# DSS_PRM register map
Vendor: Texas Instruments
Peripheral module from a debugger description file (folder omap5430_ES2_PUBLIC).
Registers are 32-bit, access not given, reset 0x30000 unless marked. A register's access mark holds for its fields unless they carry their own. Offsets are as the file gives them; lines under a group give offsets from that group; [hi:lo] are bit positions; {n}, {i} and the like mark numbered series; 'fields as' and 'values as' point back to an identical list; <NAME> marks a mode.

## DSS_PRM
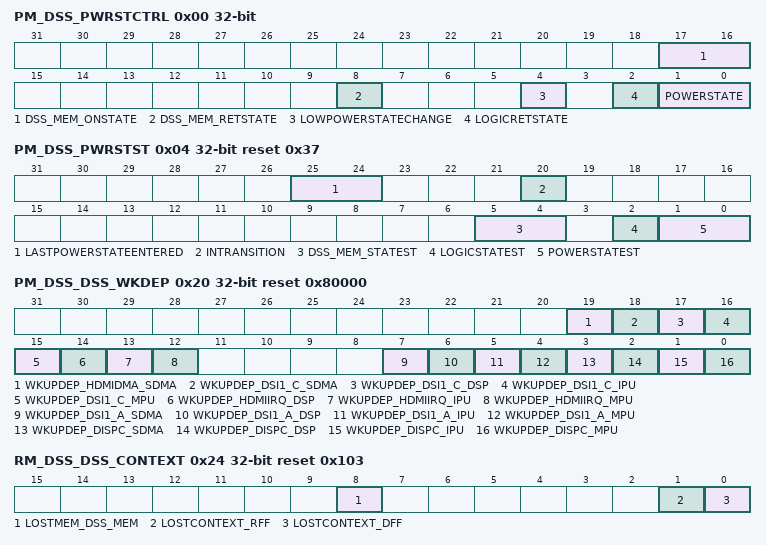
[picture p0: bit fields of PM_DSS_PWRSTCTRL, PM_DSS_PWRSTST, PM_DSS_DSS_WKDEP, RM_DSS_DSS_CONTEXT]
0x00 PM_DSS_PWRSTCTRL — This register controls the DSS power state to reach upon a domain sleep transition
  [17:16] DSS_MEM_ONSTATE ro — DSS_MEM state when domain is ON.
    3=Mem_on (Memory bank is on when the domain is ON.)
  [8] DSS_MEM_RETSTATE ro — DSS_MEM state when domain is RETENTION.
    0=mem_off (Memory bank is off when the domain is in the RETENTION state.)
  [4] LOWPOWERSTATECHANGE — Power state change request when domain has already performed a sleep transition. Allows going into deeper low power state without waking up the power domain. (access RW WSpecial)
    0=DIS (Do not request a low power state change.); 1=EN (Request a low power state change. This bit is automatically cleared when the power state is effectively changed or when power state is ON.)
  [2] LOGICRETSTATE ro — Logic state when power domain is RETENTION
    0=logic_off (Whole logic is off when the domain is in RETENTION state.)
  [1:0] POWERSTATE rw — Power state control
    0=OFF (Reserved); 1=RET (RETENTION state); 2=INACT (INACTIVE state); 3=ON (ON State)
0x04 PM_DSS_PWRSTST reset 0x37 — This register provides a status on the current DSS power domain state. [warm reset insensitive]
  [25:24] LASTPOWERSTATEENTERED — Last low power state entered. Set to 0x3 upon write of the same only. This register is intended for debug purpose only. Read 0x0: Reserved Read 0x1: Power domain was previously in RETENTION Read 0x2: Power domain was previously ON-INACTIVE Read 0x3: Power domain was previously ON-ACTIVE (access RW W1toSet)
  [20] INTRANSITION ro — Domain transition status
    0=No (No on-going transition on power domain); 1=Ongoing (Power domain transition is in progress.)
  [5:4] DSS_MEM_STATEST ro — DSS_MEM state status
    0=Mem_off (Reserved); 3=Mem_on (Memory is ON)
  [2] LOGICSTATEST ro — Logic state status
    0=OFF (Logic in domain is OFF); 1=ON (Logic in domain is ON)
  [1:0] POWERSTATEST ro — Current power state status
    0=OFF (Reserved); 1=RET (Power domain is in RETENTION); 2=INACTIVE (Power domain is ON-INACTIVE); 3=ON (Power domain is ON-ACTIVE)
0x20 PM_DSS_DSS_WKDEP access per field reset 0x80000 — This register controls wakeup dependency based on DSS service requests.
  [19] WKUPDEP_HDMIDMA_SDMA rw — Wakeup dependency from HDMI module (SWakeup_HDMI_dma signal) towards DMA_SYSTEM + L3_MAIN2 domains
    0=Disabled (Dependency is disabled); 1=Enabled (Dependency is enabled)
  [18] WKUPDEP_DSI1_C_SDMA rw — Wakeup dependency from DSI1_C module (SWakeup_DSI1_C signal) towards DMA_SYSTEM + L3_MAIN2 domains 0x0: Dependency is disabled 0x1: Dependency is enabled
  [17] WKUPDEP_DSI1_C_DSP rw — Wakeup dependency from DSI1_C module (SWakeup_DSI1_C signal) towards DSP + L3_MAIN1 + L3_MAIN2 domains 0x0: Dependency is disabled 0x1: Dependency is enabled
  [16] WKUPDEP_DSI1_C_IPU rw — Wakeup dependency from DSI1_C module (SWakeup_DSI1_C signal) towards IPU + L3_MAIN2 domains 0x0: Dependency is disabled 0x1: Dependency is enabled
  [15] WKUPDEP_DSI1_C_MPU rw — Wakeup dependency from DSI1_C module (SWakeup_DSI1_C signal) towards MPU + L3_MAIN1 + L3_MAIN2 domains 0x0: Dependency is disabled 0x1: Dependency is enabled
  [14] WKUPDEP_HDMIIRQ_DSP rw — Wakeup dependency from HDMI module (SWakeup_HDMI_irq signal) towards DSP + L3_MAIN1 + L3_MAIN2 domains
    values as WKUPDEP_HDMIDMA_SDMA
  [13] WKUPDEP_HDMIIRQ_IPU rw — Wakeup dependency from HDMI module (SWakeup_HDMI_irq signal) towards IPU + L3_MAIN2 domains
    values as WKUPDEP_HDMIDMA_SDMA
  [12] WKUPDEP_HDMIIRQ_MPU rw — Wakeup dependency from HDMI module (SWakeup_HDMI_irq signal) towards MPU + L3_MAIN1 + L3_MAIN2 domains
    values as WKUPDEP_HDMIDMA_SDMA
  [7] WKUPDEP_DSI1_A_SDMA rw — Wakeup dependency from DSI1_A module (SWakeup_DSI1_A signal) towards DMA_SYSTEM + L3_MAIN2 domains
    values as WKUPDEP_HDMIDMA_SDMA
  [6] WKUPDEP_DSI1_A_DSP rw — Wakeup dependency from DSI1_A module (SWakeup_DSI1_A signal) towards DSP + L3_MAIN1 + L3_MAIN2 domains
    values as WKUPDEP_HDMIDMA_SDMA
  [5] WKUPDEP_DSI1_A_IPU rw — Wakeup dependency from DSI1_A module (SWakeup_DSI1_A signal) towards IPU + L3_MAIN2 domains
    values as WKUPDEP_HDMIDMA_SDMA
  [4] WKUPDEP_DSI1_A_MPU rw — Wakeup dependency from DSI1_A module (SWakeup_DSI1_A signal) towards MPU + L3_MAIN1 + L3_MAIN2 domains
    values as WKUPDEP_HDMIDMA_SDMA
  [3] WKUPDEP_DISPC_SDMA rw — Wakeup dependency from DISPC module (SWakeup_DISPC signal) towards DMA_SYSTEM + L3_MAIN2 domains
    values as WKUPDEP_HDMIDMA_SDMA
  [2] WKUPDEP_DISPC_DSP rw — Wakeup dependency from DISPC module (SWakeup_DISPC signal) towards DSP + L3_MAIN1 + L3_MAIN2 domains
    values as WKUPDEP_HDMIDMA_SDMA
  [1] WKUPDEP_DISPC_IPU rw — Wakeup dependency from DISPC module (SWakeup_DISPC signal) towards IPU + L3_MAIN2 domains
    values as WKUPDEP_HDMIDMA_SDMA
  [0] WKUPDEP_DISPC_MPU rw — Wakeup dependency from DISPC module (SWakeup_DISPC signal) towards MPU + L3_MAIN1 + L3_MAIN2 domains
    values as WKUPDEP_HDMIDMA_SDMA
0x24 RM_DSS_DSS_CONTEXT reset 0x103 — This register contains dedicated DSS context statuses. [warm reset insensitive]
  [all] fields
    0=Maintained (Context has been maintained); 1=Lost (Context has been lost)
  [8] LOSTMEM_DSS_MEM — Specify if memory-based context in DSS_MEM memory bank has been lost due to a previous power transition or other reset source. (access RW W1toClr)
  [1] LOSTCONTEXT_RFF — Specify if RFF-based context has been lost due to a previous power transition or other reset source. (set upon assertion of DSS_RET_RST signal) (access RW W1toClr)
  [0] LOSTCONTEXT_DFF — Specify if DFF-based context has been lost due to a previous power transition or other reset source. (set upon assertion of DSS_RST signal) (access RW W1toClr)
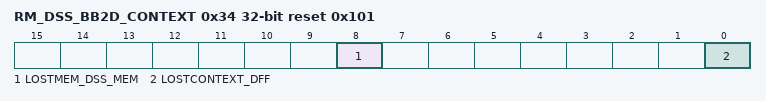
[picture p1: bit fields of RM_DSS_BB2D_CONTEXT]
0x34 RM_DSS_BB2D_CONTEXT reset 0x101 — This register contains dedicated BB2B context statuses. [warm reset insensitive]
  [8] LOSTMEM_DSS_MEM — Specify if memory-based context in DSS_MEM memory bank has been lost due to a previous power transition or other reset source. (access RW W1toClr)
    values as the fields of RM_DSS_DSS_CONTEXT
  [0] LOSTCONTEXT_DFF — Specify if DFF-based context has been lost due to a previous power transition or other reset source. (set upon assertion of DSS_RST signal) (access RW W1toClr)
    values as the fields of RM_DSS_DSS_CONTEXT
